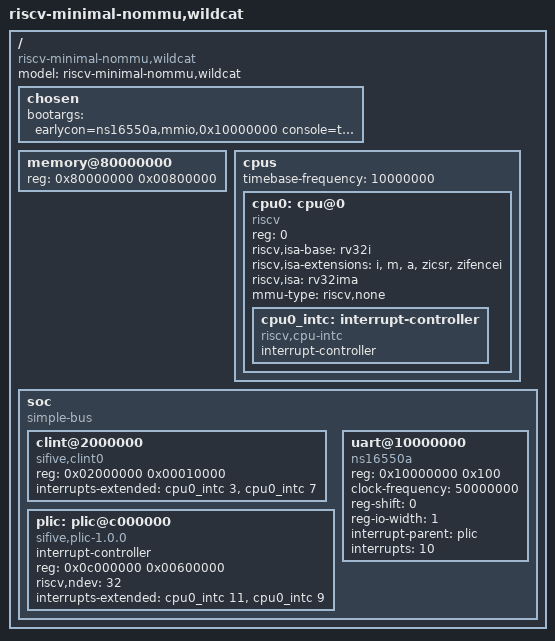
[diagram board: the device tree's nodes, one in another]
/dts-v1/;

/ {
    #address-cells = <1>;
    #size-cells    = <1>;
    compatible     = "riscv-minimal-nommu,wildcat";
    model          = "riscv-minimal-nommu,wildcat";

    chosen {
        bootargs = "earlycon=ns16550a,mmio,0x10000000 console=ttyS0 debug";
    };

    memory@80000000 {
        device_type = "memory";
        reg = <0x80000000 0x00800000>;      /* 8 MB at 0x80000000 */
    };

    cpus {
        #address-cells       = <1>;
        #size-cells          = <0>;
        timebase-frequency   = <10000000>;   /* 10 MHz, matches CLINT mtime */

        cpu0: cpu@0 {
            device_type            = "cpu";
            reg                    = <0>;
            status                 = "okay";
            compatible             = "riscv";
            riscv,isa-base         = "rv32i";
            riscv,isa-extensions   = "i", "m", "a", "zicsr", "zifencei";
            riscv,isa              = "rv32ima";    /* kept for older tooling */
            mmu-type               = "riscv,none";

            cpu0_intc: interrupt-controller {
                #interrupt-cells    = <1>;
                interrupt-controller;
                compatible          = "riscv,cpu-intc";
            };
        };
    };

    soc {
        #address-cells = <1>;
        #size-cells    = <1>;
        compatible     = "simple-bus";
        ranges;

        clint@2000000 {
            compatible          = "sifive,clint0", "riscv,clint0";
            reg                 = <0x02000000 0x00010000>;
            interrupts-extended = <&cpu0_intc 3>, <&cpu0_intc 7>;
        };

        plic: plic@c000000 {
            compatible          = "sifive,plic-1.0.0", "riscv,plic0";
            #address-cells      = <0>;
            #interrupt-cells    = <1>;
            interrupt-controller;
            reg                 = <0x0c000000 0x00600000>;
            riscv,ndev          = <32>;
            interrupts-extended = <&cpu0_intc 11>, <&cpu0_intc 9>;
        };

        uart@10000000 {
            compatible       = "ns16550a";
            reg              = <0x10000000 0x100>;
            clock-frequency  = <50000000>;
            reg-shift        = <0>;
            reg-io-width     = <1>;
            interrupt-parent = <&plic>;
            interrupts       = <10>;
        };
    };
};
